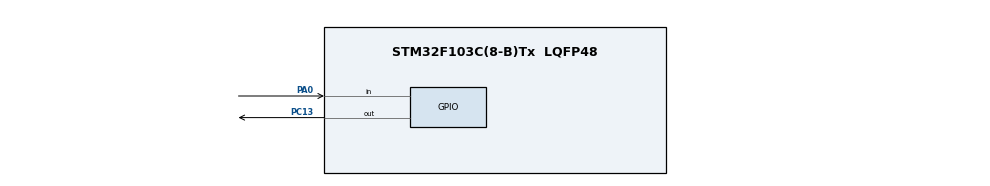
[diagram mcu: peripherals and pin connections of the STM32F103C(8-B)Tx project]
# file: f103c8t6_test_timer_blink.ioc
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Mcu.Family=STM32F1
Mcu.Name=STM32F103C(8-B)Tx
Mcu.Package=LQFP48
NVIC.PriorityGroup=NVIC_PRIORITYGROUP_4
NVIC.TIM4_IRQn=true\:0\:0\:false\:false\:true\:true\:true
PA0-WKUP.Signal=GPIO_Input
PA13.Mode=Serial_Wire
PA13.Signal=SYS_JTMS-SWDIO
PA14.Mode=Serial_Wire
PA14.Signal=SYS_JTCK-SWCLK
PC13-TAMPER-RTC.Signal=GPIO_Output
PD0-OSC_IN.Mode=HSE-External-Oscillator
PD0-OSC_IN.Signal=RCC_OSC_IN
PD1-OSC_OUT.Mode=HSE-External-Oscillator
PD1-OSC_OUT.Signal=RCC_OSC_OUT
ProjectManager.HeapSize=0x200
ProjectManager.StackSize=0x400
ProjectManager.TargetToolchain=STM32CubeIDE
RCC.APB1Freq_Value=8000000
RCC.APB2Freq_Value=8000000
RCC.PLLSourceVirtual=RCC_PLLSOURCE_HSE
RCC.SYSCLKSource=RCC_SYSCLKSOURCE_HSE
RCC.USBFreq_Value=16000000
TIM4.AutoReloadPreload=TIM_AUTORELOAD_PRELOAD_ENABLE
TIM4.Period=399
TIM4.Prescaler=1000
VP_TIM4_VS_ClockSourceINT.Mode=Internal
board=custom

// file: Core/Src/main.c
/* USER CODE BEGIN Header */
/**
  ******************************************************************************
  * @file           : main.c
  * @brief          : Main program body
  ******************************************************************************
  * @attention
  *
  * <h2><center>&copy; Copyright (c) 2020 STMicroelectronics.
  * All rights reserved.</center></h2>
  *
  * This software component is licensed by ST under BSD 3-Clause license,
  * the "License"; You may not use this file except in compliance with the
  * License. You may obtain a copy of the License at:
  *                        opensource.org/licenses/BSD-3-Clause
  *
  ******************************************************************************
  */
/* USER CODE END Header */

#include "main.h"

TIM_HandleTypeDef htim4;

void SystemClock_Config(void);
static void MX_GPIO_Init(void);
static void MX_TIM4_Init(void);

/* USER CODE BEGIN 0 */
uint32_t htim4_Init_Period = 7999;
/* USER CODE END 0 */

int main(void)
{

  /* MCU Configuration--------------------------------------------------------*/

  /* Reset of all peripherals, Initializes the Flash interface and the Systick. */
  HAL_Init();

  /* Configure the system clock */
  SystemClock_Config();

  /* Initialize all configured peripherals */
  MX_GPIO_Init();
  MX_TIM4_Init();
  /* USER CODE BEGIN 2 */
  HAL_TIM_Base_Start_IT(&htim4);
  /* USER CODE END 2 */

  /* Infinite loop */
  /* USER CODE BEGIN WHILE */
  while (1)
  {
//	  HAL_GPIO_TogglePin(GPIOC, GPIO_PIN_13);
//	  HAL_Delay(200);
//	  if(HAL_GPIO_ReadPin(GPIOA, GPIO_PIN_0)== GPIO_PIN_RESET){
//		  HAL_GPIO_WritePin(GPIOC, GPIO_PIN_13, GPIO_PIN_SET);
//	  }else{
//		  HAL_GPIO_WritePin(GPIOC, GPIO_PIN_13, GPIO_PIN_RESET);
//	  }
	  HAL_Delay(5000);

	  htim4_Init_Period = 399;

	  TIM4->PSC = 1000;
//	  TIM4->ARR = 399;
	  TIM4->ARR = htim4_Init_Period;
	  TIM4->EGR = TIM_EGR_UG;

	  HAL_Delay(5000);

	  htim4_Init_Period = 7999;

	  TIM4->PSC = 1000;
//	  TIM4->ARR = 399;
	  TIM4->ARR = htim4_Init_Period;
	  TIM4->EGR = TIM_EGR_UG;

//	  if(HAL_GPIO_ReadPin(GPIOA, GPIO_PIN_0)== GPIO_PIN_SET){
////	  		  HAL_GPIO_WritePin(GPIOC, GPIO_PIN_13, GPIO_PIN_SET);
////		  TIM4->ARR=399;
//		  htim4_Init_Period = 399;
//
//	  }
    /* USER CODE END WHILE */

  }
}

void SystemClock_Config(void)
{
  RCC_OscInitTypeDef RCC_OscInitStruct = {0};
  RCC_ClkInitTypeDef RCC_ClkInitStruct = {0};

  /** Initializes the CPU, AHB and APB busses clocks
  */
  RCC_OscInitStruct.OscillatorType = RCC_OSCILLATORTYPE_HSE;
  RCC_OscInitStruct.HSEState = RCC_HSE_ON;
  RCC_OscInitStruct.PLL.PLLState = RCC_PLL_NONE;
  if (HAL_RCC_OscConfig(&RCC_OscInitStruct) != HAL_OK)
  {
    Error_Handler();
  }
  /** Initializes the CPU, AHB and APB busses clocks
  */
  RCC_ClkInitStruct.ClockType = RCC_CLOCKTYPE_HCLK|RCC_CLOCKTYPE_SYSCLK
                              |RCC_CLOCKTYPE_PCLK1|RCC_CLOCKTYPE_PCLK2;
  RCC_ClkInitStruct.SYSCLKSource = RCC_SYSCLKSOURCE_HSE;
  RCC_ClkInitStruct.AHBCLKDivider = RCC_SYSCLK_DIV1;
  RCC_ClkInitStruct.APB1CLKDivider = RCC_HCLK_DIV1;
  RCC_ClkInitStruct.APB2CLKDivider = RCC_HCLK_DIV1;

  if (HAL_RCC_ClockConfig(&RCC_ClkInitStruct, FLASH_LATENCY_0) != HAL_OK)
  {
    Error_Handler();
  }
}

static void MX_TIM4_Init(void)
{

  TIM_ClockConfigTypeDef sClockSourceConfig = {0};
  TIM_MasterConfigTypeDef sMasterConfig = {0};

  htim4.Instance = TIM4;
  htim4.Init.Prescaler = 1000;
  htim4.Init.CounterMode = TIM_COUNTERMODE_UP;
  htim4.Init.Period = htim4_Init_Period;
  htim4.Init.ClockDivision = TIM_CLOCKDIVISION_DIV1;
  htim4.Init.AutoReloadPreload = TIM_AUTORELOAD_PRELOAD_ENABLE;
  if (HAL_TIM_Base_Init(&htim4) != HAL_OK)
  {
    Error_Handler();
  }
  sClockSourceConfig.ClockSource = TIM_CLOCKSOURCE_INTERNAL;
  if (HAL_TIM_ConfigClockSource(&htim4, &sClockSourceConfig) != HAL_OK)
  {
    Error_Handler();
  }
  sMasterConfig.MasterOutputTrigger = TIM_TRGO_RESET;
  sMasterConfig.MasterSlaveMode = TIM_MASTERSLAVEMODE_DISABLE;
  if (HAL_TIMEx_MasterConfigSynchronization(&htim4, &sMasterConfig) != HAL_OK)
  {
    Error_Handler();
  }

}

static void MX_GPIO_Init(void)
{
  GPIO_InitTypeDef GPIO_InitStruct = {0};

  /* GPIO Ports Clock Enable */
  __HAL_RCC_GPIOC_CLK_ENABLE();
  __HAL_RCC_GPIOD_CLK_ENABLE();
  __HAL_RCC_GPIOA_CLK_ENABLE();

  /*Configure GPIO pin Output Level */
  HAL_GPIO_WritePin(GPIOC, GPIO_PIN_13, GPIO_PIN_RESET);

  /*Configure GPIO pin : PC13 */
  GPIO_InitStruct.Pin = GPIO_PIN_13;
  GPIO_InitStruct.Mode = GPIO_MODE_OUTPUT_PP;
  GPIO_InitStruct.Pull = GPIO_NOPULL;
  GPIO_InitStruct.Speed = GPIO_SPEED_FREQ_LOW;
  HAL_GPIO_Init(GPIOC, &GPIO_InitStruct);

  /*Configure GPIO pin : PA0 */
  GPIO_InitStruct.Pin = GPIO_PIN_0;
  GPIO_InitStruct.Mode = GPIO_MODE_INPUT;
  GPIO_InitStruct.Pull = GPIO_NOPULL;
  HAL_GPIO_Init(GPIOA, &GPIO_InitStruct);

}

/* USER CODE BEGIN 4 */
void HAL_TIM_PeriodElapsedCallback(TIM_HandleTypeDef *htim)
{
	if(htim->Instance == TIM4)
	{
			HAL_GPIO_TogglePin(GPIOC, GPIO_PIN_13);
	}
}
/* USER CODE END 4 */

void Error_Handler(void)
{
}

/************************ (C) COPYRIGHT STMicroelectronics *****END OF FILE****/
